VERSION ""

NS_ :

BS_:
BU_:
BO_ 402772111 1801D08F_DCDC_status: 8 Vector__XXX
   SG_ DC_DC_voltage : 7|16@0+ (0.1,0) [0|6553.5] "V" Vector__XXX
   SG_ DC_DC_current : 23|16@0+ (0.1,0) [0|6553.5] "A" Vector__XXX
   SG_ DCDC_ready : 32|1@1+ (1,0) [0|1] "" Vector__XXX
   SG_ DCDC_status : 33|1@1+ (1,0) [0|1] "" Vector__XXX
   SG_ DCDC_hard_fault : 34|1@1+ (1,0) [0|1] "" Vector__XXX
   SG_ DCDC_error_can : 35|1@1+ (1,0) [0|1] "" Vector__XXX
   SG_ DCDC_fan_or_water : 36|1@1+ (1,0) [0|1] "" Vector__XXX
   SG_ DCDC_stop_error : 37|1@1+ (1,0) [0|1] "" Vector__XXX
   SG_ DCDC_fan_and_water : 38|1@1+ (1,0) [0|1] "" Vector__XXX
   SG_ DCDC_HVIL_ERROR : 39|1@1+ (1,0) [0|1] "" Vector__XXX
   SG_ DCDC_warm_temp : 40|1@1+ (1,0) [0|1] "" Vector__XXX
   SG_ DCDC_over_temp : 41|1@1+ (1,0) [0|1] "" Vector__XXX
   SG_ DCDC_over_volt_input : 42|1@1+ (1,0) [0|1] "" Vector__XXX
   SG_ DCDC_low_volt_input : 43|1@1+ (1,0) [0|1] "" Vector__XXX
   SG_ DCDC_over_volt_output : 44|1@1+ (1,0) [0|1] "" Vector__XXX
   SG_ DCDC_low_volt_output : 45|1@1+ (1,0) [0|1] "" Vector__XXX
   SG_ DCDC_over_cur_output : 46|1@1+ (1,0) [0|1] "" Vector__XXX
   SG_ DCDC_temperature : 56|8@1+ (0.1,0) [0|25.5] "°C" Vector__XXX

BO_ 419385573 18FF50E5_Charger_status: 8 Vector__XXX
   SG_ HVDC_output_voltage : 7|16@0+ (0.1,0) [0|6553.5] "V" Vector__XXX
   SG_ HVDC_output_current : 23|16@0+ (0.1,0) [0|6553.5] "A" Vector__XXX
   SG_ HW_protection : 32|1@1+ (1,0) [0|1] "" Vector__XXX
   SG_ Temperature_protection : 33|1@1+ (1,0) [0|1] "" Vector__XXX
   SG_ Input_voltage_status : 34|2@1+ (1,0) [0|3] "" Vector__XXX
   SG_ Output_under_voltage : 36|1@1+ (1,0) [0|1] "" Vector__XXX
   SG_ Output_over_voltage : 37|1@1+ (1,0) [0|1] "" Vector__XXX
   SG_ Output_over_current : 38|1@1+ (1,0) [0|1] "" Vector__XXX
   SG_ Output_short_circuit : 39|1@1+ (1,0) [0|1] "" Vector__XXX
   SG_ Communication_status : 40|1@1+ (1,0) [0|1] "" Vector__XXX
   SG_ Working_status : 41|2@1+ (1,0) [0|3] "" Vector__XXX
   SG_ Init_completion : 43|1@1+ (1,0) [0|1] "" Vector__XXX
   SG_ Fan_enable : 44|1@1+ (1,0) [0|1] "" Vector__XXX
   SG_ Cooling_pump_fan_enable : 45|1@1+ (1,0) [0|1] "" Vector__XXX
   SG_ CC_signal_status : 48|2@1+ (1,0) [0|3] "" Vector__XXX
   SG_ CP_signal_status : 50|1@1+ (1,0) [0|1] "" Vector__XXX
   SG_ charge_socket_over_heat : 51|1@1+ (1,0) [0|1] "" Vector__XXX
   SG_ Electronic_lock_state : 52|3@1+ (1,0) [0|4] "" Vector__XXX
   SG_ S2_SW_ctrl_bit_status : 55|1@1+ (1,0) [0|1] "" Vector__XXX
   SG_ Temperature : 56|8@1+ (1,-40) [-40|215] "°C" Vector__XXX

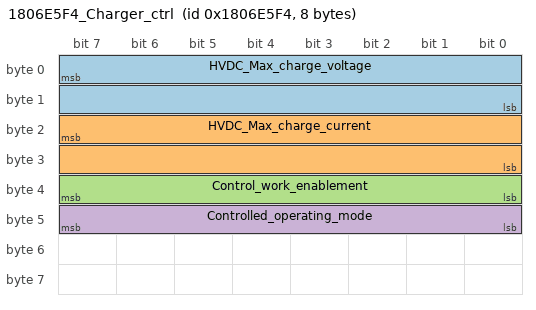
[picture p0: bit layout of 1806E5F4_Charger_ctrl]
BO_ 403105268 1806E5F4_Charger_ctrl: 8 Vector__XXX
   SG_ HVDC_Max_charge_voltage : 7|16@0+ (0.1,0) [0|6553.5] "V" Vector__XXX
   SG_ HVDC_Max_charge_current : 23|16@0+ (0.1,0) [0|6553.5] "A" Vector__XXX
   SG_ Control_work_enablement : 32|8@1+ (1,0) [0|255] "" Vector__XXX
   SG_ Controlled_operating_mode : 40|8@1+ (1,0) [0|255] "" Vector__XXX

BA_DEF_ "GenMsgCycleTime" INT 0 10000;
BA_DEF_ BO_ "GenMsgBackgroundColor" STRING ;
BA_DEF_ BO_ "GenMsgForegroundColor" STRING ;
BA_DEF_ BO_ "labelfilters" INT 0 0;
BA_DEF_ BO_ "labelfilters" INT 0 0;
BA_ "GenMsgCycleTime" BO_ 402772111 100;
BA_DEF_DEF_ "GenMsgBackgroundColor" "#ffffff";
BA_DEF_DEF_ "GenMsgForegroundColor" "#000000";
BA_DEF_DEF_ "labelfilters" 1;
BA_DEF_DEF_ "labelfilters" 1;
CM_ BO_ 402772111 "CAN message for ID 0x1801D08F with DC-DC voltage, current, temperature, and fault signals.";
CM_ SG_ 402772111 DC_DC_voltage "DCDC output voltage with a resolution of 0.1 Volts/bit.";
CM_ SG_ 402772111 DC_DC_current "DCDC output current with a resolution of 0.1 Amps/bit.";
CM_ SG_ 402772111 DCDC_ready "DCDC readiness signal: 0 = uncompleted, 1 = completed.";
CM_ SG_ 402772111 DCDC_status "DCDC status signal: 0 = stop, 1 = work.";
CM_ SG_ 402772111 DCDC_hard_fault "DCDC hard fault: 0 = No Error, 1 = Error.";
CM_ SG_ 402772111 DCDC_error_can "DCDC CAN communication error: 0 = No Error, 1 = Error.";
CM_ SG_ 402772111 DCDC_fan_or_water "DCDC fan or water status: 0 = Off, 1 = On.";
CM_ SG_ 402772111 DCDC_stop_error "DCDC stop error: 0 = No Error, 1 = Error.";
CM_ SG_ 402772111 DCDC_fan_and_water "DCDC fan and water status: 0 = FAN OFF, 1 = FAN ON.";
CM_ SG_ 402772111 DCDC_HVIL_ERROR "DCDC HVIL error: 0 = Lock Accomplish, 1 = Non Lock.";
CM_ SG_ 402772111 DCDC_warm_temp "DCDC warm temperature status: 0 = No Warm, 1 = Warm.";
CM_ SG_ 402772111 DCDC_over_temp "DCDC over temperature error: 0 = No Error, 1 = Error.";
CM_ SG_ 402772111 DCDC_over_volt_input "DCDC over voltage input error: 0 = No Error, 1 = Error.";
CM_ SG_ 402772111 DCDC_low_volt_input "DCDC low voltage input error: 0 = No Error, 1 = Error.";
CM_ SG_ 402772111 DCDC_over_volt_output "DCDC over voltage output error: 0 = No Error, 1 = Error.";
CM_ SG_ 402772111 DCDC_low_volt_output "DCDC low voltage output error: 0 = No Error, 1 = Error.";
CM_ SG_ 402772111 DCDC_over_cur_output "DCDC over current output error: 0 = No Error, 1 = Error.";
CM_ SG_ 402772111 DCDC_temperature "DCDC temperature with a resolution of 0.1 degrees/bit.";
CM_ BO_ 419385573 "CAN message for ID 0x18FF50E5 with HVDC voltage, current, and fault signals.";
CM_ SG_ 419385573 HVDC_output_voltage "HVDC output voltage with a resolution of 0.1 Volts/bit.";
CM_ SG_ 419385573 HVDC_output_current "HVDC output current with a resolution of 0.1 Amps/bit.";
CM_ SG_ 419385573 HW_protection "HVDC hardware protection status: 0 = Normal, 1 = HW protection.";
CM_ SG_ 419385573 Temperature_protection "HVDC internal temperature protection status: 0 = Normal, 1 = Internal temp protection.";
CM_ SG_ 419385573 Input_voltage_status "HVDC input voltage status: 0 = Normal, 1 = Input under voltage, 2 = Input over voltage, 3 = No input voltage.";
CM_ SG_ 419385573 Output_under_voltage "HVDC output under voltage status: 0 = Normal, 1 = Fault.";
CM_ SG_ 419385573 Output_over_voltage "HVDC output over voltage status: 0 = Normal, 1 = Fault.";
CM_ SG_ 419385573 Output_over_current "HVDC output over current status: 0 = Normal, 1 = Fault.";
CM_ SG_ 419385573 Output_short_circuit "HVDC output short circuit status: 0 = Normal, 1 = Fault.";
CM_ SG_ 419385573 Communication_status "HVDC communication status: 0 = Normal, 1 = Receiver timeout.";
CM_ SG_ 419385573 Working_status "HVDC working status: 0 = Undefined, 1 = Work, 2 = Stop, 3 = Stop or Standby.";
CM_ SG_ 419385573 Init_completion "HVDC initialization completion status: 0 = Init is not complete, 1 = Init is complete.";
CM_ SG_ 419385573 Fan_enable "HVDC fan enable status: 0 = Close, 1 = Open.";
CM_ SG_ 419385573 Cooling_pump_fan_enable "HVDC cooling pump fan enable status: 0 = Close, 1 = Open.";
CM_ SG_ 419385573 CC_signal_status "CC signal connection status: 0 = Not connected, 1 = Half connected, 2 = Normal connected, 3 = Resistance detection error.";
CM_ SG_ 419385573 CP_signal_status "CP signal status: 0 = No CP signal, 1 = CP signal is normal.";
CM_ SG_ 419385573 charge_socket_over_heat "Charge socket overheat status: 0 = Normal, 1 = Over temperature protection.";
CM_ SG_ 419385573 Electronic_lock_state "Electronic lock state: 0 = In judgement, 1 = Locked, 2 = Unlocked, 3 = Unlock fault, 4 = Locked fault.";
CM_ SG_ 419385573 S2_SW_ctrl_bit_status "S2 switch control bit status: 0 = switch off, 1 = close up.";
CM_ SG_ 419385573 Temperature "HVDC temperature with resolution of 1 degree Celsius and an offset of -40.";
CM_ BO_ 403105268 "HVDC message containing maximum charge voltage, current values, and control work enablement.";
CM_ SG_ 403105268 HVDC_Max_charge_voltage "Maximum allowable HVDC charge voltage with a resolution of 0.1 V/bit.";
CM_ SG_ 403105268 HVDC_Max_charge_current "Maximum allowable HVDC charge current with a resolution of 0.1 A/bit.";
CM_ SG_ 403105268 Control_work_enablement "Control work enablement: 0 = Charger is starting to charge, 1 = Charger close the output, 2 = Charge end/sleep, others = In vain.";
CM_ SG_ 403105268 Controlled_operating_mode "Controlled operating mode: 0 = Charging mode, 1 = Heating mode, others = In vain.";
VAL_ 402772111 DCDC_ready 0 "uncompleted" 1 "completed";
VAL_ 402772111 DCDC_status 0 "stop" 1 "work";
VAL_ 402772111 DCDC_hard_fault 0 "No Error" 1 "Error";
VAL_ 402772111 DCDC_error_can 0 "No Error" 1 "Error";
VAL_ 402772111 DCDC_fan_or_water 0 "Off" 1 "On";
VAL_ 402772111 DCDC_stop_error 0 "No Error" 1 "Error";
VAL_ 402772111 DCDC_fan_and_water 0 "FAN OFF" 1 "FAN ON";
VAL_ 402772111 DCDC_HVIL_ERROR 0 "Lock Accomplish" 1 "Non Lock";
VAL_ 402772111 DCDC_warm_temp 0 "No Warm" 1 "Warm";
VAL_ 402772111 DCDC_over_temp 0 "No Error" 1 "Error";
VAL_ 402772111 DCDC_over_volt_input 0 "No Error" 1 "Error";
VAL_ 402772111 DCDC_low_volt_input 0 "No Error" 1 "Error";
VAL_ 402772111 DCDC_over_volt_output 0 "No Error" 1 "Error";
VAL_ 402772111 DCDC_low_volt_output 0 "No Error" 1 "Error";
VAL_ 402772111 DCDC_over_cur_output 0 "No Error" 1 "Error";
VAL_ 419385573 HW_protection 0 "Normal" 1 "HW protection";
VAL_ 419385573 Temperature_protection 0 "Normal" 1 "Internal temp protection";
VAL_ 419385573 Input_voltage_status 0 "Normal" 1 "Input under voltage" 2 "Input over voltage" 3 "No input voltage";
VAL_ 419385573 Output_under_voltage 0 "Normal" 1 "Fault";
VAL_ 419385573 Output_over_voltage 0 "Normal" 1 "Fault";
VAL_ 419385573 Output_over_current 0 "Normal" 1 "Fault";
VAL_ 419385573 Output_short_circuit 0 "Normal" 1 "Fault";
VAL_ 419385573 Communication_status 0 "Normal" 1 "Receiver timeout";
VAL_ 419385573 Working_status 0 "Undefined" 1 "Work" 2 "Stop" 3 "Stop or Standby";
VAL_ 419385573 Init_completion 0 "Init is not complete" 1 "Init is complete";
VAL_ 419385573 Fan_enable 0 "Close" 1 "Open";
VAL_ 419385573 Cooling_pump_fan_enable 0 "Close" 1 "Open";
VAL_ 419385573 CC_signal_status 0 "Not connected" 1 "Half connected" 2 "Normal connected" 3 "Resistance detection error";
VAL_ 419385573 CP_signal_status 0 "No CP signal" 1 "CP signal is normal";
VAL_ 419385573 charge_socket_over_heat 0 "Normal" 1 "Over temperature protection";
VAL_ 419385573 Electronic_lock_state 0 "In judgement" 1 "Locked" 2 "Unlocked" 3 "Unlock fault" 4 "Locked fault";
VAL_ 419385573 S2_SW_ctrl_bit_status 0 "switch off" 1 "close up";
VAL_ 403105268 Control_work_enablement 0 "Charger is starting to charge" 1 "Charger close the output" 2 "Charge end/sleep" 255 "In vain";
VAL_ 403105268 Controlled_operating_mode 0 "Charging mode" 1 "Heating mode" 255 "In vain";
